# dsPIC33FJ64GS606 register map
Vendor: Microchip; Series: dsPIC33FJ64GS; File version: 1.4.228
Registers are 16-bit, read-write, no defined reset value unless marked. A register's access mark holds for its fields unless they carry their own. Offsets are from the block's base; [hi:lo] are bit positions; {n}, {i} and the like mark numbered series.

## UART2 — UART2 peripheral registers
Base 0x00000230
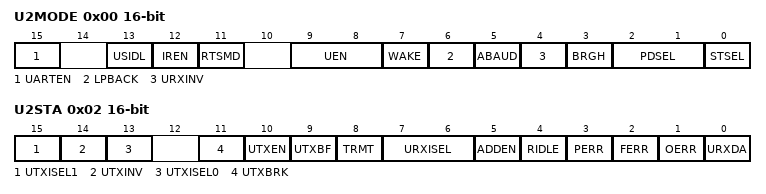
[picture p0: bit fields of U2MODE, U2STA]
0x00 U2MODE
  [15] UARTEN — UART module enable bit
  [13] USIDL — UART stop in Idle mode bit
  [12] IREN — IrDA encoder and decoder enable bit
  [11] RTSMD — RTS pin mode select bit
  [9:8] UEN — UART transmit and receive pin enable bits
  [7] WAKE — Wake-up on Start bit detect enable bit
  [6] LPBACK — Loopback mode select bit
  [5] ABAUD — Auto-baud enable bit
  [4] URXINV — Receive polarity invert bit
  [3] BRGH — High baud rate select bit
  [2:1] PDSEL — Parity and data selection bits
  [0] STSEL — Stop bit selection
0x02 U2STA
  [15] UTXISEL1 — U2STA field UTXISEL1
  [14] UTXINV — Transmit polarity invert bit
  [13] UTXISEL0 — U2STA field UTXISEL0
  [11] UTXBRK — Transmit break bit
  [10] UTXEN — Transmit enable bit
  [9] UTXBF — Transmit buffer full status bit
  [8] TRMT — Transmit shift register empty bit
  [7:6] URXISEL — Receive interrupt mode selection bits
  [5] ADDEN — Address character detect bit
  [4] RIDLE — Receiver Idle bit
  [3] PERR — Parity error status bit
  [2] FERR — Framing error status bit
  [1] OERR — Receive buffer overrun error status bit
  [0] URXDA — Receive buffer data available status bit
0x04 U2TXREG
  [n] UTXREG{n} (n=0..8) — U2TXREG field UTXREG{n}
  [8:0] U2TXREG — U2TXREG field U2TXREG
0x06 U2RXREG
  [n] URXREG{n} (n=0..8) — U2RXREG field URXREG{n}
  [8:0] U2RXREG — U2RXREG field U2RXREG
0x08 U2BRG
  [15:0] U2BRG — U2BRG register value

## SPI1 — SPI1 peripheral registers
Base 0x00000240
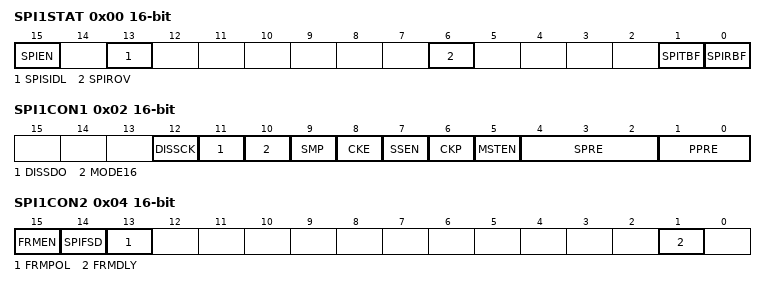
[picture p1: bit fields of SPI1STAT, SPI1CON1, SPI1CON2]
0x00 SPI1STAT
  [15] SPIEN — SPI module enable bit
  [13] SPISIDL — SPI stop in Idle mode bit
  [6] SPIROV — Receive overflow flag bit
  [1] SPITBF — SPI transmit buffer full status bit
  [0] SPIRBF — SPI receive buffer full status bit
0x02 SPI1CON1
  [12] DISSCK — Internal serial clock control bit
  [11] DISSDO — SDOx pin control bit
  [10] MODE16 — Communication word select bit
  [9] SMP — Input data sample phase bit
  [8] CKE — Serial output data change edge select bit
  [7] SSEN — Slave select enable bit
  [6] CKP — Clock polarity select bit
  [5] MSTEN — Master mode enable bit
  [4:2] SPRE — Secondary prescale bits
  [1:0] PPRE — Primary prescale bits
0x04 SPI1CON2
  [15] FRMEN — Framed SPI support enable bit
  [14] SPIFSD — Frame sync pulse direction control bit
  [13] FRMPOL — Frame sync pulse polarity bit
  [1] FRMDLY — Frame sync pulse edge select bit
0x08 SPI1BUF
  [15:0] SPI1BUF — SPI1BUF register value

## SPI2 — SPI2 peripheral registers
Base 0x00000260
Registers as SPI1 (with SPI1 read as SPI2).

## GPIOB — GPIOB peripheral registers
Base 0x000002C8
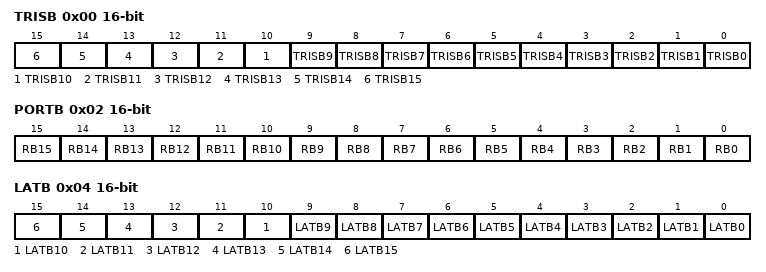
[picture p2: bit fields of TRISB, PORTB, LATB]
0x00 TRISB
  [n] TRISB{n} (n=0..15) — TRISB field TRISB{n}
0x02 PORTB
  [n] RB{n} (n=0..15) — PORTB field RB{n}
0x04 LATB
  [n] LATB{n} (n=0..15) — LATB field LATB{n}

## GPIOC — GPIOC peripheral registers
Base 0x000002D0
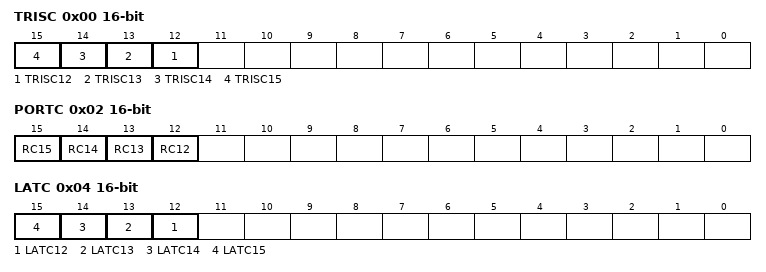
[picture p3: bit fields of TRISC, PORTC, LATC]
0x00 TRISC
  [n] TRISC{n} (n=12..15) — TRISC field TRISC{n}
0x02 PORTC
  [n] RC{n} (n=12..15) — PORTC field RC{n}
0x04 LATC
  [n] LATC{n} (n=12..15) — LATC field LATC{n}

## GPIOD — GPIOD peripheral registers
Base 0x000002D8
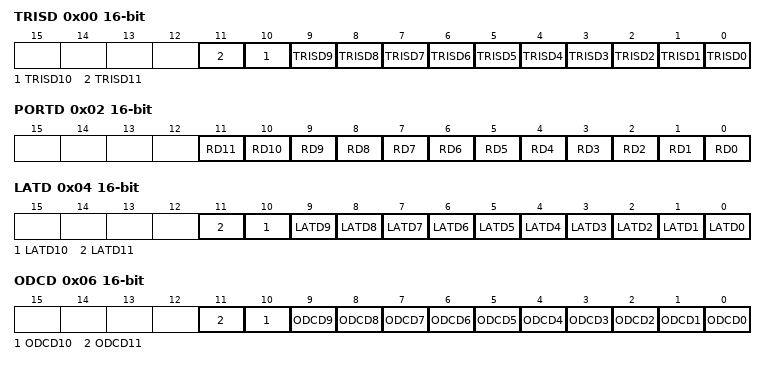
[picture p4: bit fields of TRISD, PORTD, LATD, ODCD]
0x00 TRISD
  [n] TRISD{n} (n=0..11) — TRISD field TRISD{n}
0x02 PORTD
  [n] RD{n} (n=0..11) — PORTD field RD{n}
0x04 LATD
  [n] LATD{n} (n=0..11) — LATD field LATD{n}
0x06 ODCD
  [n] ODCD{n} (n=0..11) — ODCD field ODCD{n}

## GPIOE — GPIOE peripheral registers
Base 0x000002E0
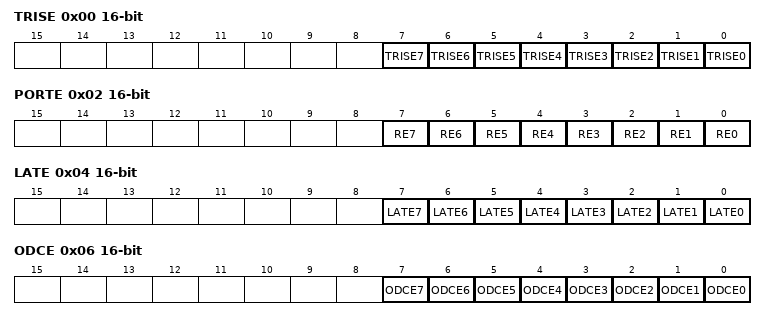
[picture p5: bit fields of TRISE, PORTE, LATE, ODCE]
0x00 TRISE
  [n] TRISE{n} (n=0..7) — TRISE field TRISE{n}
0x02 PORTE
  [n] RE{n} (n=0..7) — PORTE field RE{n}
0x04 LATE
  [n] LATE{n} (n=0..7) — LATE field LATE{n}
0x06 ODCE
  [n] ODCE{n} (n=0..7) — ODCE field ODCE{n}
